# STM32F777xx register map
File version: 1.0
Registers are 32-bit, read-write, reset 0x0 unless marked. A register's access mark holds for its fields unless they carry their own. Offsets are from the block's base; [hi:lo] are bit positions; {n}, {i} and the like mark numbered series.

## JPEG — JPEG Codec
Base 0x50051000
0x00 CONFR0 — JPEG Codec Control Register (JPEG_CONFR0)
  [0] START — Start/Stop bit
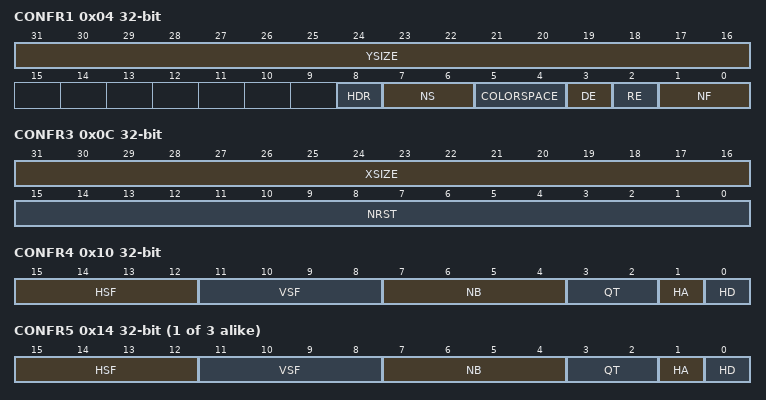
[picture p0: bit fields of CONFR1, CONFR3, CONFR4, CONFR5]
0x04 CONFR1 — JPEG Codec Control Register (JPEG_CONFR1)
  [31:16] YSIZE — Number of lines in source image
  [8] HDR — Header Processing On/Off
  [7:6] NS — Number of components for Scan
  [5:4] COLORSPACE
  [3] DE — Decoding Enable
  [2] RE — Restart maker Enable
  [1:0] NF — Number of color components
0x08 CONFR2 — JPEG Codec Control Register (JPEG_CONFR2)
  [25:0] NMCU — Number of MCU units minus 1 to encode
0x0C CONFR3 — JPEG Codec Control Register (JPEG_CONFR3)
  [31:16] XSIZE — Number of pixels per line
  [15:0] NRST — Number of MCU between two restart makers minus 1
0x10 CONFR4 — JPEG Codec Control Register (JPEG_CONFR4)
  [15:12] HSF — Horizontal sampling factor for component 1
  [11:8] VSF — Vertical sampling factor for component 1
  [7:4] NB — Number of data units minus 1 that belong to a particular color in the MCU
  [3:2] QT — Selects quantization table associated with a color component
  [1] HA — Selects the Huffman table for encoding the AC coefficients
  [0] HD — Selects the Huffman table for encoding the DC coefficients
{0x0+4i} CONFR{i} (i=5..7) — JPEG Codec Control Register (JPEG_CONFR{i})
  [15:12] HSF — Horizontal sampling factor for component 2
  [11:8] VSF — Vertical sampling factor for component 2
  [7:4] NB — Number of data units minus 1 that belong to a particular color in the MCU
  [3:2] QT — Selects quantization table associated with a color component
  [1] HA — Selects the Huffman table for encoding the AC coefficients
  [0] HD — Selects the Huffman table for encoding the DC coefficients
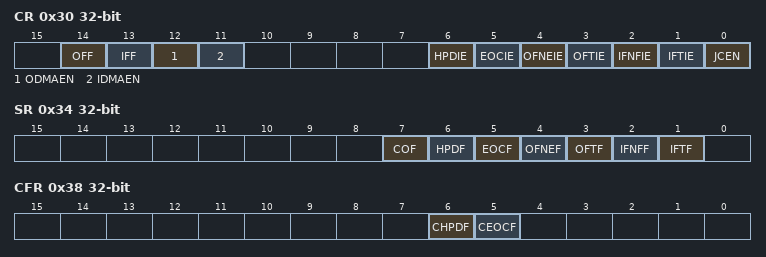
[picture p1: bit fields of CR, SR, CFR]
0x30 CR — JPEG Control Register (JPEG_CR)
  [14] OFF — Flush the output FIFO
  [13] IFF — Flush the input FIFO
  [12] ODMAEN — Enable the DMA request generation for the output FIFO
  [11] IDMAEN — Enable the DMA request generation for the input FIFO
  [6] HPDIE — Header Parsing Done Interrupt Enable
  [5] EOCIE — End of Conversion Interrupt Enable
  [4] OFNEIE — Output FIFO Not Empty Interrupt Enable
  [3] OFTIE — Output FIFO Threshold Interrupt Enable
  [2] IFNFIE — Input FIFO Not Full Interrupt Enable
  [1] IFTIE — Input FIFO Threshold Interrupt Enable
  [0] JCEN — Enable the JPEG Codec Core
0x34 SR — JPEG Status Register (JPEG_SR)
  [7] COF — JPEG Codec operation on going flag
  [6] HPDF — JPEG Codec has finished the parsing of the headers and the internal registers have been updated
  [5] EOCF — JPEG Codec core has finished the encoding or the decoding process and than last data has been sent to the output FIFO
  [4] OFNEF — Output FIFO is not empty, a data is available
  [3] OFTF — Output FIFO is not empty and has reach its threshold
  [2] IFNFF — Input FIFO Not Full Flag, a data can be written
  [1] IFTF — Input FIFO is not full and is below its threshold flag
0x38 CFR — JPEG Clear Flag Register (JPEG_CFR)
  [6] CHPDF — Clear Header Parsing Done Flag
  [5] CEOCF — Clear End of Conversion Flag
0x40 DIR — JPEG Data Input Register (JPEG_DIR)
  [31:0] DATAIN — Data Input FIFO
0x44 DOR — JPEG Data Output Register (JPEG_DOR)
  [31:0] DATAOUT — Data Output FIFO
{0x50+4i} QMEM{i:02} (i=0..9) — JPEG quantization tables 0
0x78 QMEM010 — JPEG quantization tables 0
0x7C QMEM011 — JPEG quantization tables 0
0x80 QMEM012 — JPEG quantization tables 0
0x84 QMEM013 — JPEG quantization tables 0
0x88 QMEM014 — JPEG quantization tables 0
0x8C QMEM015 — JPEG quantization tables 0
0x90 QMEM10 — JPEG quantization tables 1
0x94 QMEM11 — JPEG quantization tables 1
0x98 QMEM12 — JPEG quantization tables 1
0x9C QMEM13 — JPEG quantization tables 1
0xA0 QMEM14 — JPEG quantization tables 1
{0x68+4i} QMEM{i} (i=15..19) — JPEG quantization tables 1
0xB8 QMEM110 — JPEG quantization tables 1
0xBC QMEM111 — JPEG quantization tables 1
0xC0 QMEM112 — JPEG quantization tables 1
0xC4 QMEM113 — JPEG quantization tables 1
0xC8 QMEM114 — JPEG quantization tables 1
0xCC QMEM115 — JPEG quantization tables 1
{0x80+4i} QMEM{i} (i=20..29) — JPEG quantization tables 2
0xF8 QMEM210 — JPEG quantization tables 2
0xFC QMEM211 — JPEG quantization tables 2
0x100 QMEM212 — JPEG quantization tables 2
0x104 QMEM213 — JPEG quantization tables 2
0x108 QMEM214 — JPEG quantization tables 2
0x10C QMEM215 — JPEG quantization tables 2
{0x98+4i} QMEM{i} (i=30..39) — JPEG quantization tables 3
0x138 QMEM310 — JPEG quantization tables 3
0x13C QMEM311 — JPEG quantization tables 3
0x140 QMEM312 — JPEG quantization tables 3
0x144 QMEM313 — JPEG quantization tables 3
0x148 QMEM314 — JPEG quantization tables 3
0x14C QMEM315 — JPEG quantization tables 3
{0x150+4i} HUFFMIN{i} (i=0..15) — JPEG HuffMin tables
{0x190+4i} HUFFBASE{i} (i=0..31) — JPEG HuffSymb tables
{0x210+4i} HUFFSYMB[{i}] (i=0..83)
{0x360+4i} DHTMEM[{i}] (i=0..102)
{0x500+4i} HUFFENC_AC0[{i}] (i=0..87)
{0x660+4i} HUFFENC_AC1[{i}] (i=0..87)
{0x7C0+4i} HUFFENC_DC{i:02} (i=0..7) — JPEG encoder, DC Huffman table 0
{0x7B8+4i} HUFFENC_DC{i} (i=10..17) — JPEG encoder, DC Huffman table 1
